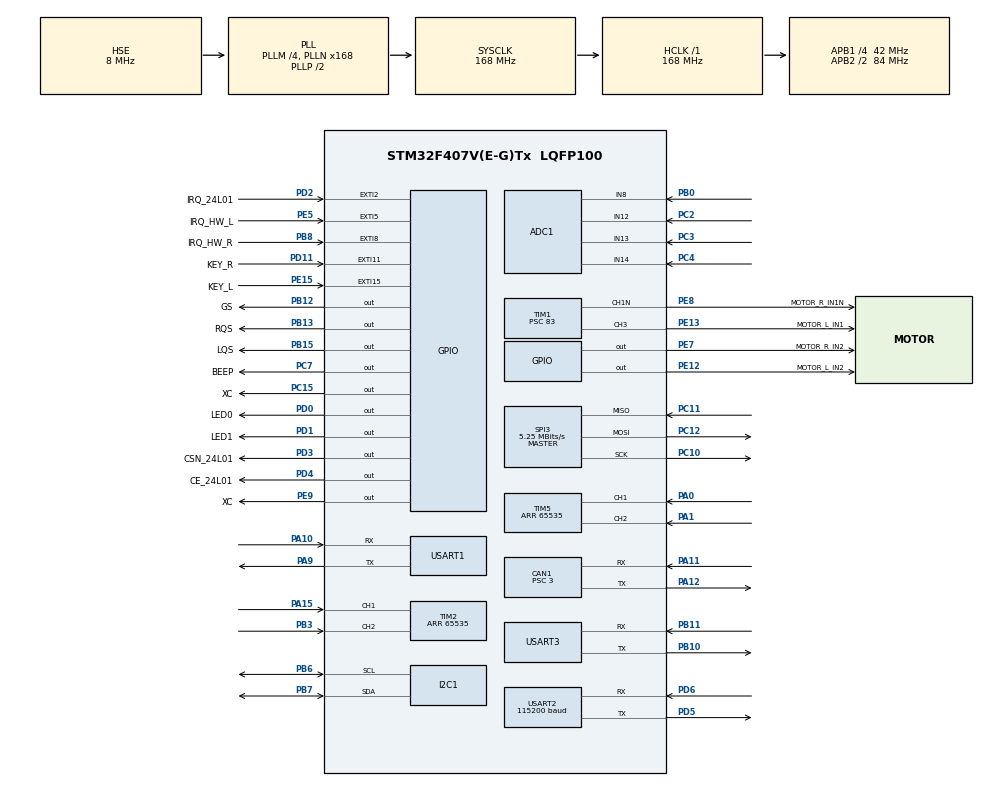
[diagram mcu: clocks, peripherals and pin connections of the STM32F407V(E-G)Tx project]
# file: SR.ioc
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ADC1.Channel-0\#ChannelRegularConversion=ADC_CHANNEL_8
ADC1.Channel-1\#ChannelRegularConversion=ADC_CHANNEL_12
ADC1.Channel-2\#ChannelRegularConversion=ADC_CHANNEL_13
ADC1.Channel-3\#ChannelRegularConversion=ADC_CHANNEL_14
ADC1.ContinuousConvMode=ENABLE
ADC1.DMAContinuousRequests=ENABLE
ADC1.DiscontinuousConvMode=DISABLE
ADC1.EnableAnalogWatchDog=true
ADC1.NbrOfConversion=4
ADC1.NbrOfConversionFlag=1
ADC1.Rank-0\#ChannelRegularConversion=1
ADC1.Rank-1\#ChannelRegularConversion=2
ADC1.Rank-2\#ChannelRegularConversion=3
ADC1.Rank-3\#ChannelRegularConversion=4
ADC1.SamplingTime-0\#ChannelRegularConversion=ADC_SAMPLETIME_56CYCLES
ADC1.SamplingTime-1\#ChannelRegularConversion=ADC_SAMPLETIME_56CYCLES
ADC1.SamplingTime-2\#ChannelRegularConversion=ADC_SAMPLETIME_56CYCLES
ADC1.SamplingTime-3\#ChannelRegularConversion=ADC_SAMPLETIME_56CYCLES
ADC1.ScanConvMode=ENABLE
ADC1.WatchdogChannel=ADC_CHANNEL_8
ADC1.master=1
CAN1.BS1=CAN_BS1_10TQ
CAN1.BS2=CAN_BS2_3TQ
CAN1.CalculateBaudRate=1000000
CAN1.CalculateTimeBit=1000
CAN1.CalculateTimeQuantum=71.42857142857143
CAN1.NART=ENABLE
CAN1.Prescaler=3
CAN1.TXFP=ENABLE
Dma.ADC1.8.Direction=DMA_PERIPH_TO_MEMORY
Dma.ADC1.8.FIFOMode=DMA_FIFOMODE_DISABLE
Dma.ADC1.8.Instance=DMA2_Stream0
Dma.ADC1.8.MemDataAlignment=DMA_MDATAALIGN_HALFWORD
Dma.ADC1.8.MemInc=DMA_MINC_ENABLE
Dma.ADC1.8.Mode=DMA_CIRCULAR
Dma.ADC1.8.PeriphDataAlignment=DMA_PDATAALIGN_HALFWORD
Dma.ADC1.8.PeriphInc=DMA_PINC_DISABLE
Dma.ADC1.8.Priority=DMA_PRIORITY_LOW
Dma.Request0=USART1_RX
Dma.Request1=USART1_TX
Dma.Request2=USART2_RX
Dma.Request3=USART2_TX
Dma.Request4=USART3_RX
Dma.Request5=USART3_TX
Dma.Request6=SPI3_RX
Dma.Request7=SPI3_TX
Dma.Request8=ADC1
Dma.SPI3_RX.6.Direction=DMA_PERIPH_TO_MEMORY
Dma.SPI3_RX.6.FIFOMode=DMA_FIFOMODE_ENABLE
Dma.SPI3_RX.6.FIFOThreshold=DMA_FIFO_THRESHOLD_FULL
Dma.SPI3_RX.6.Instance=DMA1_Stream2
Dma.SPI3_RX.6.MemBurst=DMA_MBURST_SINGLE
Dma.SPI3_RX.6.MemDataAlignment=DMA_MDATAALIGN_BYTE
Dma.SPI3_RX.6.MemInc=DMA_MINC_ENABLE
Dma.SPI3_RX.6.Mode=DMA_NORMAL
Dma.SPI3_RX.6.PeriphBurst=DMA_PBURST_SINGLE
Dma.SPI3_RX.6.PeriphDataAlignment=DMA_PDATAALIGN_BYTE
Dma.SPI3_RX.6.PeriphInc=DMA_PINC_DISABLE
Dma.SPI3_RX.6.Priority=DMA_PRIORITY_LOW
Dma.SPI3_TX.7.Direction=DMA_MEMORY_TO_PERIPH
Dma.SPI3_TX.7.FIFOMode=DMA_FIFOMODE_ENABLE
Dma.SPI3_TX.7.FIFOThreshold=DMA_FIFO_THRESHOLD_FULL
Dma.SPI3_TX.7.Instance=DMA1_Stream7
Dma.SPI3_TX.7.MemBurst=DMA_MBURST_SINGLE
Dma.SPI3_TX.7.MemDataAlignment=DMA_MDATAALIGN_BYTE
Dma.SPI3_TX.7.MemInc=DMA_MINC_ENABLE
Dma.SPI3_TX.7.Mode=DMA_NORMAL
Dma.SPI3_TX.7.PeriphBurst=DMA_PBURST_SINGLE
Dma.SPI3_TX.7.PeriphDataAlignment=DMA_PDATAALIGN_BYTE
Dma.SPI3_TX.7.PeriphInc=DMA_PINC_DISABLE
Dma.SPI3_TX.7.Priority=DMA_PRIORITY_LOW
Dma.USART1_RX.0.Direction=DMA_PERIPH_TO_MEMORY
Dma.USART1_RX.0.FIFOMode=DMA_FIFOMODE_ENABLE
Dma.USART1_RX.0.FIFOThreshold=DMA_FIFO_THRESHOLD_FULL
Dma.USART1_RX.0.Instance=DMA2_Stream2
Dma.USART1_RX.0.MemBurst=DMA_MBURST_SINGLE
Dma.USART1_RX.0.MemDataAlignment=DMA_MDATAALIGN_BYTE
Dma.USART1_RX.0.MemInc=DMA_MINC_ENABLE
Dma.USART1_RX.0.Mode=DMA_NORMAL
Dma.USART1_RX.0.PeriphBurst=DMA_PBURST_SINGLE
Dma.USART1_RX.0.PeriphDataAlignment=DMA_PDATAALIGN_BYTE
Dma.USART1_RX.0.PeriphInc=DMA_PINC_DISABLE
Dma.USART1_RX.0.Priority=DMA_PRIORITY_HIGH
Dma.USART1_TX.1.Direction=DMA_MEMORY_TO_PERIPH
Dma.USART1_TX.1.FIFOMode=DMA_FIFOMODE_ENABLE
Dma.USART1_TX.1.FIFOThreshold=DMA_FIFO_THRESHOLD_FULL
Dma.USART1_TX.1.Instance=DMA2_Stream7
Dma.USART1_TX.1.MemBurst=DMA_MBURST_SINGLE
Dma.USART1_TX.1.MemDataAlignment=DMA_MDATAALIGN_BYTE
Dma.USART1_TX.1.MemInc=DMA_MINC_ENABLE
Dma.USART1_TX.1.Mode=DMA_NORMAL
Dma.USART1_TX.1.PeriphBurst=DMA_PBURST_SINGLE
Dma.USART1_TX.1.PeriphDataAlignment=DMA_PDATAALIGN_BYTE
Dma.USART1_TX.1.PeriphInc=DMA_PINC_DISABLE
Dma.USART1_TX.1.Priority=DMA_PRIORITY_HIGH
Dma.USART2_RX.2.Direction=DMA_PERIPH_TO_MEMORY
Dma.USART2_RX.2.FIFOMode=DMA_FIFOMODE_ENABLE
Dma.USART2_RX.2.FIFOThreshold=DMA_FIFO_THRESHOLD_FULL
Dma.USART2_RX.2.Instance=DMA1_Stream5
Dma.USART2_RX.2.MemBurst=DMA_MBURST_SINGLE
Dma.USART2_RX.2.MemDataAlignment=DMA_MDATAALIGN_BYTE
Dma.USART2_RX.2.MemInc=DMA_MINC_ENABLE
Dma.USART2_RX.2.Mode=DMA_NORMAL
Dma.USART2_RX.2.PeriphBurst=DMA_PBURST_SINGLE
Dma.USART2_RX.2.PeriphDataAlignment=DMA_PDATAALIGN_BYTE
Dma.USART2_RX.2.PeriphInc=DMA_PINC_DISABLE
Dma.USART2_RX.2.Priority=DMA_PRIORITY_HIGH
Dma.USART2_TX.3.Direction=DMA_MEMORY_TO_PERIPH
Dma.USART2_TX.3.FIFOMode=DMA_FIFOMODE_ENABLE
Dma.USART2_TX.3.FIFOThreshold=DMA_FIFO_THRESHOLD_FULL
Dma.USART2_TX.3.Instance=DMA1_Stream6
Dma.USART2_TX.3.MemBurst=DMA_MBURST_SINGLE
Dma.USART2_TX.3.MemDataAlignment=DMA_MDATAALIGN_BYTE
Dma.USART2_TX.3.MemInc=DMA_MINC_ENABLE
Dma.USART2_TX.3.Mode=DMA_NORMAL
Dma.USART2_TX.3.PeriphBurst=DMA_PBURST_SINGLE
Dma.USART2_TX.3.PeriphDataAlignment=DMA_PDATAALIGN_BYTE
Dma.USART2_TX.3.PeriphInc=DMA_PINC_DISABLE
Dma.USART2_TX.3.Priority=DMA_PRIORITY_LOW
Dma.USART3_RX.4.Direction=DMA_PERIPH_TO_MEMORY
Dma.USART3_RX.4.FIFOMode=DMA_FIFOMODE_ENABLE
Dma.USART3_RX.4.FIFOThreshold=DMA_FIFO_THRESHOLD_FULL
Dma.USART3_RX.4.Instance=DMA1_Stream1
Dma.USART3_RX.4.MemBurst=DMA_MBURST_SINGLE
Dma.USART3_RX.4.MemDataAlignment=DMA_MDATAALIGN_BYTE
Dma.USART3_RX.4.MemInc=DMA_MINC_ENABLE
Dma.USART3_RX.4.Mode=DMA_NORMAL
Dma.USART3_RX.4.PeriphBurst=DMA_PBURST_SINGLE
Dma.USART3_RX.4.PeriphDataAlignment=DMA_PDATAALIGN_BYTE
Dma.USART3_RX.4.PeriphInc=DMA_PINC_DISABLE
Dma.USART3_RX.4.Priority=DMA_PRIORITY_LOW
Dma.USART3_TX.5.Direction=DMA_MEMORY_TO_PERIPH
Dma.USART3_TX.5.FIFOMode=DMA_FIFOMODE_ENABLE
Dma.USART3_TX.5.FIFOThreshold=DMA_FIFO_THRESHOLD_FULL
Dma.USART3_TX.5.Instance=DMA1_Stream3
Dma.USART3_TX.5.MemBurst=DMA_MBURST_SINGLE
Dma.USART3_TX.5.MemDataAlignment=DMA_MDATAALIGN_BYTE
Dma.USART3_TX.5.MemInc=DMA_MINC_ENABLE
Dma.USART3_TX.5.Mode=DMA_NORMAL
Dma.USART3_TX.5.PeriphBurst=DMA_PBURST_SINGLE
Dma.USART3_TX.5.PeriphDataAlignment=DMA_PDATAALIGN_BYTE
Dma.USART3_TX.5.PeriphInc=DMA_PINC_DISABLE
Dma.USART3_TX.5.Priority=DMA_PRIORITY_LOW
FREERTOS.Tasks01=defaultTask,24,128,StartDefaultTask,Default,NULL,Dynamic,NULL,NULL
FREERTOS.configENABLE_FPU=1
FREERTOS.configMAX_TASK_NAME_LEN=32
I2C1.I2C_Mode=I2C_Fast
Mcu.Family=STM32F4
Mcu.Name=STM32F407V(E-G)Tx
Mcu.Package=LQFP100
NVIC.CAN1_RX0_IRQn=true\:5\:0\:false\:false\:true\:true\:true\:true\:true
NVIC.CAN1_RX1_IRQn=true\:5\:0\:false\:false\:true\:true\:true\:true\:true
NVIC.DMA1_Stream1_IRQn=true\:5\:0\:false\:false\:true\:true\:false\:true\:true
NVIC.DMA1_Stream2_IRQn=true\:5\:0\:false\:false\:true\:false\:false\:true\:true
NVIC.DMA1_Stream3_IRQn=true\:5\:0\:false\:false\:true\:true\:false\:true\:true
NVIC.DMA1_Stream5_IRQn=true\:5\:0\:false\:false\:true\:true\:false\:true\:true
NVIC.DMA1_Stream6_IRQn=true\:5\:0\:false\:false\:true\:true\:false\:true\:true
NVIC.DMA1_Stream7_IRQn=true\:5\:0\:false\:false\:true\:true\:false\:true\:true
NVIC.DMA2_Stream0_IRQn=true\:5\:0\:false\:false\:true\:true\:false\:true\:true
NVIC.DMA2_Stream2_IRQn=true\:5\:0\:false\:false\:true\:true\:false\:true\:true
NVIC.DMA2_Stream7_IRQn=true\:5\:0\:false\:false\:true\:true\:false\:true\:true
NVIC.EXTI15_10_IRQn=true\:5\:0\:true\:false\:true\:true\:true\:true\:true
NVIC.EXTI2_IRQn=true\:5\:0\:false\:false\:true\:true\:true\:true\:true
NVIC.EXTI9_5_IRQn=true\:5\:0\:false\:false\:true\:true\:true\:true\:true
NVIC.PriorityGroup=NVIC_PRIORITYGROUP_4
NVIC.SPI3_IRQn=true\:5\:0\:false\:false\:true\:true\:true\:true\:true
NVIC.TIM5_IRQn=true\:5\:0\:false\:false\:true\:true\:true\:true\:true
NVIC.TIM8_TRG_COM_TIM14_IRQn=true\:15\:0\:false\:false\:true\:false\:false\:true\:true
NVIC.TimeBase=TIM8_TRG_COM_TIM14_IRQn
NVIC.TimeBaseIP=TIM14
NVIC.USART1_IRQn=true\:5\:0\:false\:false\:true\:true\:true\:true\:true
NVIC.USART2_IRQn=true\:5\:0\:false\:false\:true\:true\:true\:true\:true
NVIC.USART3_IRQn=true\:5\:0\:false\:false\:true\:true\:true\:true\:true
PA0-WKUP.GPIO_PuPd=GPIO_NOPULL
PA0-WKUP.GPIO_Speed=GPIO_SPEED_FREQ_LOW
PA0-WKUP.Signal=S_TIM5_CH1
PA1.GPIO_PuPd=GPIO_NOPULL
PA1.GPIO_Speed=GPIO_SPEED_FREQ_LOW
PA1.Signal=S_TIM5_CH2
PA10.Mode=Asynchronous
PA10.Signal=USART1_RX
PA11.Mode=CAN_Activate
PA11.Signal=CAN1_RX
PA12.Mode=CAN_Activate
PA12.Signal=CAN1_TX
PA13.Mode=Serial_Wire
PA13.Signal=SYS_JTMS-SWDIO
PA14.Mode=Serial_Wire
PA14.Signal=SYS_JTCK-SWCLK
PA15.GPIO_PuPd=GPIO_NOPULL
PA15.GPIO_Speed=GPIO_SPEED_FREQ_LOW
PA15.Signal=S_TIM2_CH1_ETR
PA9.Mode=Asynchronous
PA9.Signal=USART1_TX
PB0.Signal=ADCx_IN8
PB10.Mode=Asynchronous
PB10.Signal=USART3_TX
PB11.Mode=Asynchronous
PB11.Signal=USART3_RX
PB12.GPIO_Label=GS
PB12.Signal=GPIO_Output
PB13.GPIO_Label=RQS
PB13.Signal=GPIO_Output
PB15.GPIO_Label=LQS
PB15.Signal=GPIO_Output
PB3.GPIO_PuPd=GPIO_NOPULL
PB3.GPIO_Speed=GPIO_SPEED_FREQ_LOW
PB3.Signal=S_TIM2_CH2
PB6.Mode=I2C
PB6.Signal=I2C1_SCL
PB7.Mode=I2C
PB7.Signal=I2C1_SDA
PB8.GPIO_Label=IRQ_HW_R
PB8.GPIO_ModeDefaultEXTI=GPIO_MODE_IT_FALLING
PB8.GPIO_PuPd=GPIO_NOPULL
PB8.Signal=GPXTI8
PC10.Mode=Full_Duplex_Master
PC10.Signal=SPI3_SCK
PC11.Mode=Full_Duplex_Master
PC11.Signal=SPI3_MISO
PC12.Mode=Full_Duplex_Master
PC12.Signal=SPI3_MOSI
PC15-OSC32_OUT.GPIO_Label=XC
PC15-OSC32_OUT.Signal=GPIO_Output
PC2.Signal=ADCx_IN12
PC3.Signal=ADCx_IN13
PC4.Signal=ADCx_IN14
PC7.GPIO_Label=BEEP
PC7.Signal=GPIO_Output
PD0.GPIO_Label=LED0
PD0.PinState=GPIO_PIN_SET
PD0.Signal=GPIO_Output
PD1.GPIO_Label=LED1
PD1.PinState=GPIO_PIN_SET
PD1.Signal=GPIO_Output
PD11.GPIO_Label=KEY_R
PD11.GPIO_ModeDefaultEXTI=GPIO_MODE_IT_FALLING
PD11.GPIO_PuPd=GPIO_PULLUP
PD11.Signal=GPXTI11
PD2.GPIO_Label=IRQ_24L01
PD2.GPIO_ModeDefaultEXTI=GPIO_MODE_IT_FALLING
PD2.GPIO_PuPd=GPIO_PULLUP
PD2.Signal=GPXTI2
PD3.GPIO_Label=CSN_24L01
PD3.GPIO_Speed=GPIO_SPEED_FREQ_HIGH
PD3.PinState=GPIO_PIN_SET
PD3.Signal=GPIO_Output
PD4.GPIO_Label=CE_24L01
PD4.GPIO_Speed=GPIO_SPEED_FREQ_HIGH
PD4.PinState=GPIO_PIN_SET
PD4.Signal=GPIO_Output
PD5.Mode=Asynchronous
PD5.Signal=USART2_TX
PD6.Mode=Asynchronous
PD6.Signal=USART2_RX
PE12.GPIO_Label=MOTOR_L_IN2
PE12.Signal=GPIO_Output
PE13.GPIO_Label=MOTOR_L_IN1
PE13.Signal=S_TIM1_CH3
PE15.GPIO_Label=KEY_L
PE15.GPIO_ModeDefaultEXTI=GPIO_MODE_IT_FALLING
PE15.GPIO_PuPd=GPIO_PULLUP
PE15.Signal=GPXTI15
PE5.GPIO_Label=IRQ_HW_L
PE5.GPIO_ModeDefaultEXTI=GPIO_MODE_IT_FALLING
PE5.GPIO_PuPd=GPIO_NOPULL
PE5.Signal=GPXTI5
PE7.GPIO_Label=MOTOR_R_IN2
PE7.Signal=GPIO_Output
PE8.GPIO_Label=MOTOR_R_IN1N
PE8.Mode=PWM Generation1 CH1N
PE8.Signal=TIM1_CH1N
PE9.GPIO_Label=XC
PE9.Signal=GPIO_Output
PH0-OSC_IN.Mode=HSE-External-Oscillator
PH0-OSC_IN.Signal=RCC_OSC_IN
PH1-OSC_OUT.Mode=HSE-External-Oscillator
PH1-OSC_OUT.Signal=RCC_OSC_OUT
ProjectManager.HeapSize=0x200
ProjectManager.StackSize=0x400
ProjectManager.TargetToolchain=Makefile
RCC.48MHZClocksFreq_Value=84000000
RCC.AHBFreq_Value=168000000
RCC.APB1CLKDivider=RCC_HCLK_DIV4
RCC.APB1Freq_Value=42000000
RCC.APB1TimFreq_Value=84000000
RCC.APB2CLKDivider=RCC_HCLK_DIV2
RCC.APB2Freq_Value=84000000
RCC.APB2TimFreq_Value=168000000
RCC.CortexFreq_Value=168000000
RCC.HCLKFreq_Value=168000000
RCC.HSE_VALUE=8000000
RCC.HSI_VALUE=16000000
RCC.LSE_VALUE=32768
RCC.PLLM=4
RCC.PLLN=168
RCC.PLLSourceVirtual=RCC_PLLSOURCE_HSE
RCC.SYSCLKFreq_VALUE=168000000
RCC.SYSCLKSource=RCC_SYSCLKSOURCE_PLLCLK
RCC.VCOOutputFreq_Value=336000000
SH.ADCx_IN12.0=ADC1_IN12,IN12
SH.ADCx_IN13.0=ADC1_IN13,IN13
SH.ADCx_IN14.0=ADC1_IN14,IN14
SH.ADCx_IN8.0=ADC1_IN8,IN8
SH.S_TIM1_CH3.0=TIM1_CH3,PWM Generation3 CH3
SH.S_TIM2_CH1_ETR.0=TIM2_CH1,Encoder_Interface
SH.S_TIM2_CH2.0=TIM2_CH2,Encoder_Interface
SH.S_TIM5_CH1.0=TIM5_CH1,Encoder_Interface
SH.S_TIM5_CH2.0=TIM5_CH2,Encoder_Interface
SPI3.BaudRatePrescaler=SPI_BAUDRATEPRESCALER_8
SPI3.CalculateBaudRate=5.25 MBits/s
SPI3.Direction=SPI_DIRECTION_2LINES
SPI3.Mode=SPI_MODE_MASTER
SPI3.VirtualType=VM_MASTER
STMicroelectronics.X-CUBE-ALGOBUILD.1.3.0.LibraryCcDSPOoLibraryJjDSPOoLibrary=true
TIM1.AutoReloadPreload=TIM_AUTORELOAD_PRELOAD_ENABLE
TIM1.Channel-PWM\ Generation1\ CH1N=TIM_CHANNEL_1
TIM1.Channel-PWM\ Generation3\ CH3=TIM_CHANNEL_3
TIM1.Period=999
TIM1.Prescaler=83
TIM2.AutoReloadPreload=TIM_AUTORELOAD_PRELOAD_DISABLE
TIM2.EncoderMode=TIM_ENCODERMODE_TI12
TIM2.IC1Filter=15
TIM2.IC1Polarity=TIM_ICPOLARITY_RISING
TIM2.IC2Filter=15
TIM2.IC2Polarity=TIM_ICPOLARITY_RISING
TIM2.Period=65535
TIM5.AutoReloadPreload=TIM_AUTORELOAD_PRELOAD_DISABLE
TIM5.EncoderMode=TIM_ENCODERMODE_TI12
TIM5.IC1Filter=15
TIM5.IC2Filter=15
TIM5.Period=65535
USART1.VirtualMode=VM_ASYNC
USART2.BaudRate=115200
USART2.VirtualMode=VM_ASYNC
USART3.VirtualMode=VM_ASYNC
VP_CRC_VS_CRC.Mode=CRC_Activate
VP_FREERTOS_VS_CMSIS_V2.Mode=CMSIS_V2
VP_STMicroelectronics.X-CUBE-ALGOBUILD_VS_DSPOoLibraryJjLibrary_1.3.0_1.3.0.Mode=DSPOoLibraryJjLibrary
VP_SYS_VS_tim14.Mode=TIM14
VP_TIM1_VS_ClockSourceINT.Mode=Internal
board=custom

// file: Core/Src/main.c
/* USER CODE BEGIN Header */
/**
  ******************************************************************************
  * @file           : main.c
  * @brief          : Main program body
  ******************************************************************************
  * @attention
  *
  * Copyright (c) 2025 STMicroelectronics.
  * All rights reserved.
  *
  * This software is licensed under terms that can be found in the LICENSE file
  * in the root directory of this software component.
  * If no LICENSE file comes with this software, it is provided AS-IS.
  *
  ******************************************************************************
  */
/* USER CODE END Header */
#include "main.h"
#include "cmsis_os.h"
#include "adc.h"
#include "can.h"
#include "crc.h"
#include "dma.h"
#include "i2c.h"
#include "spi.h"
#include "tim.h"
#include "usart.h"
#include "gpio.h"

void SystemClock_Config(void);
void MX_FREERTOS_Init(void);

int main(void)
{

  /* MCU Configuration--------------------------------------------------------*/

  /* Reset of all peripherals, Initializes the Flash interface and the Systick. */
  HAL_Init();

  /* Configure the system clock */
  SystemClock_Config();

  /* Initialize all configured peripherals */
  MX_GPIO_Init();
  MX_DMA_Init();
  MX_USART1_UART_Init();
  MX_I2C1_Init();
  MX_USART2_UART_Init();
  MX_USART3_UART_Init();
  MX_CAN1_Init();
  MX_SPI3_Init();
  MX_TIM1_Init();
  MX_ADC1_Init();
  MX_CRC_Init();
  MX_TIM2_Init();
  MX_TIM5_Init();

  /* Init scheduler */
  osKernelInitialize();

  /* Call init function for freertos objects (in cmsis_os2.c) */
  MX_FREERTOS_Init();

  /* Start scheduler */
  osKernelStart();

  /* We should never get here as control is now taken by the scheduler */

  /* Infinite loop */
  while (1)
  {

  }
}

void SystemClock_Config(void)
{
  RCC_OscInitTypeDef RCC_OscInitStruct = {0};
  RCC_ClkInitTypeDef RCC_ClkInitStruct = {0};

  /** Configure the main internal regulator output voltage
  */
  __HAL_RCC_PWR_CLK_ENABLE();
  __HAL_PWR_VOLTAGESCALING_CONFIG(PWR_REGULATOR_VOLTAGE_SCALE1);

  /** Initializes the RCC Oscillators according to the specified parameters
  * in the RCC_OscInitTypeDef structure.
  */
  RCC_OscInitStruct.OscillatorType = RCC_OSCILLATORTYPE_HSE;
  RCC_OscInitStruct.HSEState = RCC_HSE_ON;
  RCC_OscInitStruct.PLL.PLLState = RCC_PLL_ON;
  RCC_OscInitStruct.PLL.PLLSource = RCC_PLLSOURCE_HSE;
  RCC_OscInitStruct.PLL.PLLM = 4;
  RCC_OscInitStruct.PLL.PLLN = 168;
  RCC_OscInitStruct.PLL.PLLP = RCC_PLLP_DIV2;
  RCC_OscInitStruct.PLL.PLLQ = 4;
  if (HAL_RCC_OscConfig(&RCC_OscInitStruct) != HAL_OK)
  {
    Error_Handler();
  }

  /** Initializes the CPU, AHB and APB buses clocks
  */
  RCC_ClkInitStruct.ClockType = RCC_CLOCKTYPE_HCLK|RCC_CLOCKTYPE_SYSCLK
                              |RCC_CLOCKTYPE_PCLK1|RCC_CLOCKTYPE_PCLK2;
  RCC_ClkInitStruct.SYSCLKSource = RCC_SYSCLKSOURCE_PLLCLK;
  RCC_ClkInitStruct.AHBCLKDivider = RCC_SYSCLK_DIV1;
  RCC_ClkInitStruct.APB1CLKDivider = RCC_HCLK_DIV4;
  RCC_ClkInitStruct.APB2CLKDivider = RCC_HCLK_DIV2;

  if (HAL_RCC_ClockConfig(&RCC_ClkInitStruct, FLASH_LATENCY_5) != HAL_OK)
  {
    Error_Handler();
  }
}

void HAL_TIM_PeriodElapsedCallback(TIM_HandleTypeDef *htim)
{
  if (htim->Instance == TIM14)
  {
    HAL_IncTick();
  }
}

void Error_Handler(void)
{
  __disable_irq();
  while (1)
  {
  }
}

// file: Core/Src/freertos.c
/* USER CODE BEGIN Header */
/**
 ******************************************************************************
 * File Name          : freertos.c
 * Description        : Code for freertos applications
 ******************************************************************************
 * @attention
 *
 * Copyright (c) 2025 STMicroelectronics.
 * All rights reserved.
 *
 * This software is licensed under terms that can be found in the LICENSE file
 * in the root directory of this software component.
 * If no LICENSE file comes with this software, it is provided AS-IS.
 *
 ******************************************************************************
 */
/* USER CODE END Header */

#include "FreeRTOS.h"
#include "task.h"
#include "main.h"
#include "cmsis_os.h"

/* USER CODE BEGIN Includes */
#include "robot.h" // Include the robot's header file for hardware initialization
/* USER CODE END Includes */

/* Definitions for defaultTask */
osThreadId_t defaultTaskHandle;
const osThreadAttr_t defaultTask_attributes = {
  .name = "defaultTask",
  .stack_size = 128 * 4,
  .priority = (osPriority_t) osPriorityNormal,
};

void StartDefaultTask(void *argument);

void MX_FREERTOS_Init(void); /* (MISRA C 2004 rule 8.1) */

void MX_FREERTOS_Init(void) {
  /* USER CODE BEGIN Init */
    Robot_Init(); // Initialize the robot's hardware and peripherals
  /* USER CODE END Init */

  /* Create the thread(s) */
  /* creation of defaultTask */
  defaultTaskHandle = osThreadNew(StartDefaultTask, NULL, &defaultTask_attributes);

}

void StartDefaultTask(void *argument)
{
    for (;;) {
        osDelay(1);
    }
}
